AUTOSAR XML (schema 4-0-3)
standard types defined: Boolean, UInt16, UInt32
package /AUTOSAR_Platform/DataConstrs
  range DC_Boolean: raw 0..1
  range DC_UInt16: raw 0..65535
package /PATAC/MSM/ComponentTypes
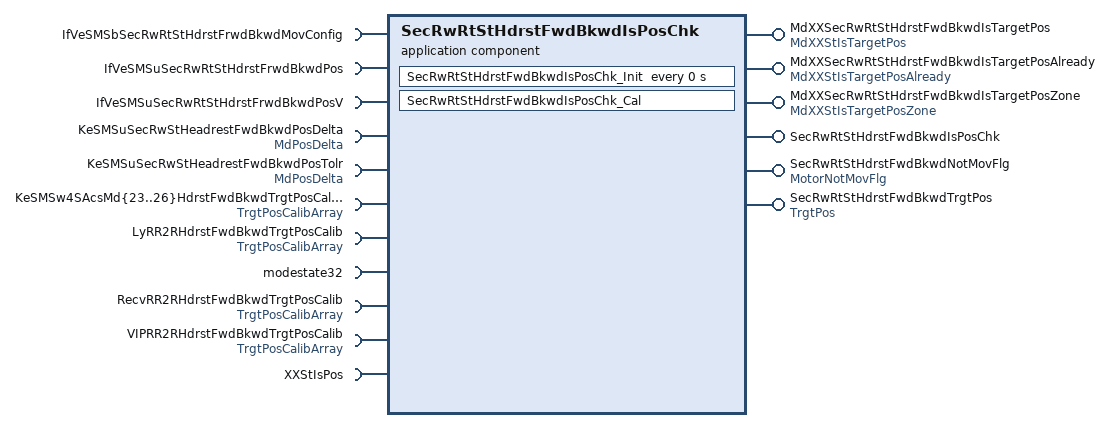
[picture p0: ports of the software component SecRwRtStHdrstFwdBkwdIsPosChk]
  application sw component type SecRwRtStHdrstFwdBkwdIsPosChk
    6 x provide port:
      MdXXSecRwRtStHdrstFwdBkwdIsTargetPos: nonqueued-sender-com-spec=data-element=MdXXStIsTargetPos/Val, provided-interface=MdXXStIsTargetPos
      MdXXSecRwRtStHdrstFwdBkwdIsTargetPosAlready: nonqueued-sender-com-spec=data-element=MdXXStIsTargetPosAlready/Val, provided-interface=MdXXStIsTargetPosAlready
      MdXXSecRwRtStHdrstFwdBkwdIsTargetPosZone: nonqueued-sender-com-spec=data-element=MdXXStIsTargetPosZone/Val, provided-interface=MdXXStIsTargetPosZone
      SecRwRtStHdrstFwdBkwdIsPosChk: server-com-spec{operation=Cal, queue-length=1}, provided-interface=SecRwRtStHdrstFwdBkwdIsPosChk
      SecRwRtStHdrstFwdBkwdNotMovFlg: nonqueued-sender-com-spec{data-element=MotorNotMovFlg/Val, init-value=0}, provided-interface=MotorNotMovFlg
      SecRwRtStHdrstFwdBkwdTrgtPos: nonqueued-sender-com-spec{data-element=TrgtPos/Val, init-value=4095}, provided-interface=TrgtPos
    14 x require port:
      IfVeSMSbSecRwRtStHdrstFrwdBkwdMovConfig: nonqueued-receiver-com-spec{data-element=IfVeSMSbSecRwRtStHdrstFrwdBkwdMovConfig/Val, filter=data-filter-type=ALWAYS, init-value=0}, required-interface=IfVeSMSbSecRwRtStHdrstFrwdBkwdMovConfig
      IfVeSMSuSecRwRtStHdrstFrwdBkwdPos: nonqueued-receiver-com-spec{data-element=IfVeSMSuSecRwRtStHdrstFrwdBkwdPos/Val, filter=data-filter-type=ALWAYS, init-value=0}, required-interface=IfVeSMSuSecRwRtStHdrstFrwdBkwdPos
      IfVeSMSuSecRwRtStHdrstFrwdBkwdPosV: nonqueued-receiver-com-spec{data-element=IfVeSMSuSecRwRtStHdrstFrwdBkwdPosV/Val, filter=data-filter-type=ALWAYS, init-value=0}, required-interface=IfVeSMSuSecRwRtStHdrstFrwdBkwdPosV
      KeSMSuSecRwStHeadrestFwdBkwdPosDelta: parameter-require-com-spec{init-value=150, parameter=Val}, required-interface=MdPosDelta
      KeSMSuSecRwStHeadrestFwdBkwdPosTolr: parameter-require-com-spec{init-value=150, parameter=Val}, required-interface=MdPosDelta
      KeSMSw4SAcsMd{23..26}HdrstFwdBkwdTrgtPosCalib: nonqueued-receiver-com-spec{data-element=TrgtPosArray, filter=data-filter-type=ALWAYS, init-value=[4095, 4095, 4095]}, required-interface=TrgtPosCalibArray
      LyRR2RHdrstFwdBkwdTrgtPosCalib: nonqueued-receiver-com-spec{data-element=TrgtPosArray, filter=data-filter-type=ALWAYS, init-value=[4095, 4095, 4095]}, required-interface=TrgtPosCalibArray
      modestate32: nonqueued-receiver-com-spec{data-element=modestate32/Val, filter=data-filter-type=ALWAYS, init-value=0}, required-interface=modestate32
      RecvRR2RHdrstFwdBkwdTrgtPosCalib: nonqueued-receiver-com-spec{data-element=TrgtPosArray, filter=data-filter-type=ALWAYS, init-value=[4095, 4095, 4095]}, required-interface=TrgtPosCalibArray
      VIPRR2RHdrstFwdBkwdTrgtPosCalib: nonqueued-receiver-com-spec{data-element=TrgtPosArray, filter=data-filter-type=ALWAYS, init-value=[4095, 4095, 4095]}, required-interface=TrgtPosCalibArray
      XXStIsPos: client-com-spec=Get, required-interface=XXStIsPos
    behavior SecRwRtStHdrstFwdBkwdIsPosChk_InternalBehavior
      operation invoked event OIT_SecRwRtStHdrstFwdBkwdIsPosChk_Cal_SecRwRtStHdrstFwdBkwdIsPosChk_Cal: start-on-event=SecRwRtStHdrstFwdBkwdIsPosChk_Cal, operation=SecRwRtStHdrstFwdBkwdIsPosChk.Cal
      timing event SecRwRtStHdrstFwdBkwdIsPosChk_InitEvent: start-on-event=SecRwRtStHdrstFwdBkwdIsPosChk_Init, period=0
      runnable SecRwRtStHdrstFwdBkwdIsPosChk_Cal
        data-receive-point-by-arguments:
          11 x access:
            REC_IfVeSMSbSecRwRtStHdrstFrwdBkwdMovConfig_Val: accessed-variable=IfVeSMSbSecRwRtStHdrstFrwdBkwdMovConfig.Val
            REC_IfVeSMSuSecRwRtStHdrstFrwdBkwdPos_Val: accessed-variable=IfVeSMSuSecRwRtStHdrstFrwdBkwdPos.Val
            REC_IfVeSMSuSecRwRtStHdrstFrwdBkwdPosV_Val: accessed-variable=IfVeSMSuSecRwRtStHdrstFrwdBkwdPosV.Val
            REC_KeSMSw4SAcsMd{23..26}HdrstFwdBkwdTrgtPosCalib_TrgtPosArray: accessed-variable=KeSMSw4SAcsMd{23..26}HdrstFwdBkwdTrgtPosCalib.TrgtPosArray
            REC_LyRR2RHdrstFwdBkwdTrgtPosCalib_TrgtPosArray: accessed-variable=LyRR2RHdrstFwdBkwdTrgtPosCalib.TrgtPosArray
            REC_modestate32_Val: accessed-variable=modestate32.Val
            REC_RecvRR2RHdrstFwdBkwdTrgtPosCalib_TrgtPosArray: accessed-variable=RecvRR2RHdrstFwdBkwdTrgtPosCalib.TrgtPosArray
            REC_VIPRR2RHdrstFwdBkwdTrgtPosCalib_TrgtPosArray: accessed-variable=VIPRR2RHdrstFwdBkwdTrgtPosCalib.TrgtPosArray
        data-send-points:
          5 x access:
            SEND_MdXXSecRwRtStHdrstFwdBkwdIsTargetPos_Val: accessed-variable=MdXXSecRwRtStHdrstFwdBkwdIsTargetPos.Val
            SEND_MdXXSecRwRtStHdrstFwdBkwdIsTargetPosAlready_Val: accessed-variable=MdXXSecRwRtStHdrstFwdBkwdIsTargetPosAlready.Val
            SEND_MdXXSecRwRtStHdrstFwdBkwdIsTargetPosZone_Val: accessed-variable=MdXXSecRwRtStHdrstFwdBkwdIsTargetPosZone.Val
            SEND_SecRwRtStHdrstFwdBkwdNotMovFlg_Val: accessed-variable=SecRwRtStHdrstFwdBkwdNotMovFlg.Val
            SEND_SecRwRtStHdrstFwdBkwdTrgtPos_Val: accessed-variable=SecRwRtStHdrstFwdBkwdTrgtPos.Val
        parameter access PA_KeSMSuSecRwStHeadrestFwdBkwdPosDelta_Val: accessed-parameter=KeSMSuSecRwStHeadrestFwdBkwdPosDelta.Val
        parameter access PA_KeSMSuSecRwStHeadrestFwdBkwdPosTolr_Val: accessed-parameter=KeSMSuSecRwStHeadrestFwdBkwdPosTolr.Val
        sync call SC_XXStIsPos_Get: operation=XXStIsPos.Get, timeout=0
      runnable SecRwRtStHdrstFwdBkwdIsPosChk_Init
        parameter access PA_KeSMSuSecRwStHeadrestFwdBkwdPosDelta_Val: accessed-parameter=KeSMSuSecRwStHeadrestFwdBkwdPosDelta.Val
        parameter access PA_KeSMSuSecRwStHeadrestFwdBkwdPosTolr_Val: accessed-parameter=KeSMSuSecRwStHeadrestFwdBkwdPosTolr.Val
  swc implementation SecRwRtStHdrstFwdBkwdIsPosChk_Implementation: behavior=SecRwRtStHdrstFwdBkwdIsPosChk_InternalBehavior
    code-descriptors:
      code Default: artifact-descriptors=autosar-engineering-object={short-label=Default, category=SWSRC}
package /PATAC/MSM/ModeAdjust/CalPortInterface
  parameter interface MdPosDelta
    parameter data prototype Val: sw-calibration-access=READ-WRITE, type=UInt16
package /PATAC/MSM/ModeAdjust/DataType
  impl type TrgtPosCalibArray: category=ARRAY, sw-calibration-access=READ-ONLY, type-emitter=RTE  # 0:pos 1:max 2:min
    element Element: array-size=3, array-size-semantics=FIXED-SIZE, implementation-data-type=UInt16, invalid-value=0
package /PATAC/MSM/ModeAdjust/PortInterface
  client server interface SecRwRtStHdrstFwdBkwdIsPosChk
    operation Cal
  client server interface XXStIsPos
    operation Get
      8 x arg, all with server-argument-impl-policy=USE-ARGUMENT-TYPE:
        PosV: type=DataTypes/Boolean, direction=IN
        Pos: type=UInt16, direction=IN
        CalibArray: type=TrgtPosCalibArray, direction=IN
        Delta: type=UInt16, direction=IN
        Tolr: type=UInt16, direction=IN
        IsPos: type=DataTypes/Boolean, direction=OUT
        IsPosZone: type=DataTypes/Boolean, direction=OUT
        IsPosAlready: type=DataTypes/Boolean, direction=OUT
  6 x sender receiver interface:
    MdXXStIsTargetPos: invalidation-policy{data-element=MdXXStIsTargetPos/Val, handle-invalid=DONT-INVALIDATE}
      data Val: type=UInt32
    MdXXStIsTargetPosAlready: invalidation-policy{data-element=MdXXStIsTargetPosAlready/Val, handle-invalid=DONT-INVALIDATE}
      data Val: type=UInt32
    MdXXStIsTargetPosZone: invalidation-policy{data-element=MdXXStIsTargetPosZone/Val, handle-invalid=DONT-INVALIDATE}
      data Val: type=UInt32
    modestate32: invalidation-policy{data-element=modestate32/Val, handle-invalid=DONT-INVALIDATE}
      data Val: type=UInt32
    MotorNotMovFlg: invalidation-policy{data-element=MotorNotMovFlg/Val, handle-invalid=DONT-INVALIDATE}
      data Val: type=Implementation/Boolean
    TrgtPosCalibArray: invalidation-policy{data-element=TrgtPosArray, handle-invalid=DONT-INVALIDATE}
      data TrgtPosArray: type=TrgtPosCalibArray  # 0:Pos 1:Max 2:Min
package /PATAC/MSM/PortInterfaces
  4 x sender receiver interface:
    IfVeSMSbSecRwRtStHdrstFrwdBkwdMovConfig: invalidation-policy{data-element=IfVeSMSbSecRwRtStHdrstFrwdBkwdMovConfig/Val, handle-invalid=DONT-INVALIDATE}
      data Val: type=Implementation/Boolean
    IfVeSMSuSecRwRtStHdrstFrwdBkwdPos: invalidation-policy{data-element=IfVeSMSuSecRwRtStHdrstFrwdBkwdPos/Val, handle-invalid=DONT-INVALIDATE}
      data Val: type=UInt16
    IfVeSMSuSecRwRtStHdrstFrwdBkwdPosV: invalidation-policy{data-element=IfVeSMSuSecRwRtStHdrstFrwdBkwdPosV/Val, handle-invalid=DONT-INVALIDATE}
      data Val: type=Implementation/Boolean
    TrgtPos: invalidation-policy{data-element=TrgtPos/Val, handle-invalid=DONT-INVALIDATE}
      data Val: type=UInt16
